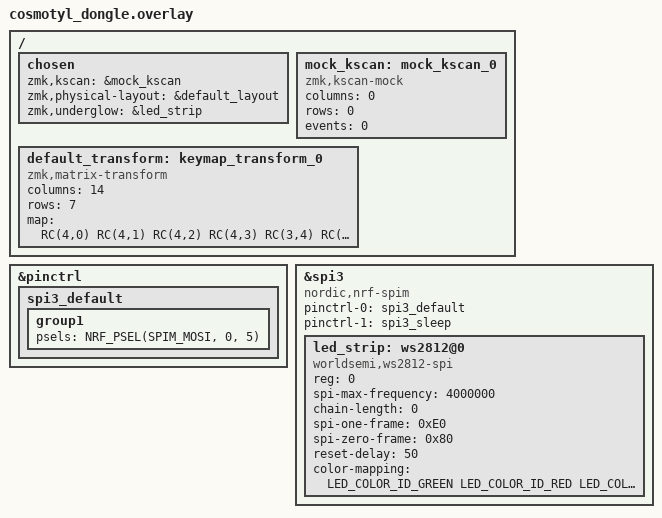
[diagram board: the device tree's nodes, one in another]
#include <dt-bindings/zmk/matrix_transform.h>
#include <dt-bindings/led/led.h>
/* #include "cosmotyl.dtsi" */
#include "cosmotyl-layouts.dtsi"


/* &spi1 { */
/*     status = "disabled"; */
/* }; */
/**/
/* &kscan0 { status = "disabled"; }; */

&pinctrl {
    spi3_default: spi3_default {
        group1 {
            psels = <NRF_PSEL(SPIM_MOSI, 0, 5)>;
        };
    };
};

&spi3 {
    compatible = "nordic,nrf-spim";
    status = "okay";

    pinctrl-0 = <&spi3_default>;
    pinctrl-1 = <&spi3_sleep>;
    pinctrl-names = "default", "sleep";

    led_strip: ws2812@0 {
        compatible = "worldsemi,ws2812-spi";

        /* SPI */
        reg = <0>; /* ignored, but necessary for SPI bindings */
        spi-max-frequency = <4000000>;

        /* WS2812 */
        chain-length = <0>;
        spi-one-frame = <0xE0>;
        spi-zero-frame = <0x80>;
        reset-delay = <50>;

        color-mapping = <LED_COLOR_ID_GREEN LED_COLOR_ID_RED LED_COLOR_ID_BLUE>;
    };
};

/ {
    chosen {
        zmk,kscan = &mock_kscan;
        zmk,physical-layout = &default_layout;
        zmk,underglow = &led_strip;
    };

    mock_kscan: mock_kscan_0 {
        compatible = "zmk,kscan-mock";
        columns = <0>;
        rows = <0>;
        events = <0>;
    };

    default_transform: keymap_transform_0 {
        compatible = "zmk,matrix-transform";
        columns = <14>;
        rows = <7>;
        map = <RC(4,0) RC(4,1) RC(4,2) RC(4,3) RC(3,4) RC(4,5) RC(4,8) RC(3,9) RC(4,10) RC(4,11) RC(4,12) RC(4,13) RC(3,0) RC(3,1) RC(3,2) RC(3,3) RC(2,4) RC(3,5) RC(3,8) RC(2,9) RC(3,10) RC(3,11) RC(3,12) RC(3,13) RC(2,0) RC(2,1) RC(2,2) RC(2,3) RC(1,4) RC(2,5) RC(2,8) RC(1,9) RC(2,10) RC(2,11) RC(2,12) RC(2,13) RC(1,0) RC(1,1) RC(1,2) RC(1,3) RC(0,4) RC(1,5) RC(1,8) RC(0,9) RC(1,10) RC(1,11) RC(1,12) RC(1,13) RC(0,0) RC(0,1) RC(0,2) RC(0,3) RC(0,10) RC(0,11) RC(0,12) RC(0,13) RC(0,5) RC(1,6) RC(1,7) RC(0,8) RC(0,6) RC(2,6) RC(2,7) RC(0,7) RC(4,6) RC(5,6) RC(5,7) RC(4,7)>;
    };
};

